# PIC16LF1773 register map
Vendor: Microchip
Registers are 8-bit, read-write, reset 0x0 unless marked. A register's access mark holds for its fields unless they carry their own. Addresses are absolute, and some are shared; only a register's first bit layout is shown; [hi:lo] are bit positions; {n}, {i} and the like mark numbered series.

## txm_mod
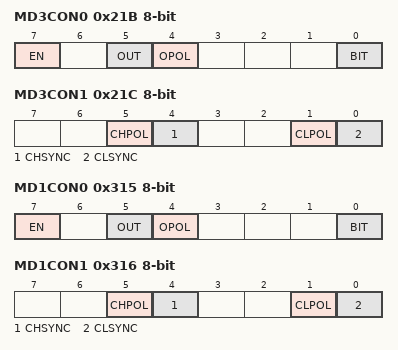
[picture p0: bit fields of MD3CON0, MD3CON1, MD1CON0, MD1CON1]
0x21B MD3CON0
  [7] EN, [5] OUT ro, [4] OPOL, [0] BIT
0x21C MD3CON1
  [5] CHPOL, [4] CHSYNC, [1] CLPOL, [0] CLSYNC
0x21D MD3SRC
  [4:0] MS
0x21E MD3CARL reset not defined — (power-on value ---x0000)
  [4:0] CL
0x21F MD3CARH reset not defined — (power-on value ---x0000)
  [4:0] CH
0x315 MD1CON0
  [7] EN, [5] OUT ro, [4] OPOL, [0] BIT
0x316 MD1CON1
  [5] CHPOL, [4] CHSYNC, [1] CLPOL, [0] CLSYNC
0x317 MD1SRC
  [4:0] MS
0x318 MD1CARL reset not defined — (power-on value ---x0000)
  [4:0] CL
0x319 MD1CARH reset not defined — (power-on value ---x0000)
  [4:0] CH
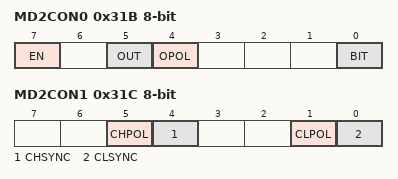
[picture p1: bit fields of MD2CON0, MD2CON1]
0x31B MD2CON0
  [7] EN, [5] OUT ro, [4] OPOL, [0] BIT
0x31C MD2CON1
  [5] CHPOL, [4] CHSYNC, [1] CLPOL, [0] CLSYNC
0x31D MD2SRC
  [4:0] MS
0x31E MD2CARL reset not defined — (power-on value ---x0000)
  [4:0] CL
0x31F MD2CARH reset not defined — (power-on value ---x0000)
  [4:0] CH

## ccp
0x291 CCPR1L reset not defined — (power-on value xxxxxxxx)
  [7:0] RL
0x292 CCPR1H reset not defined — (power-on value xxxxxxxx)
  [7:0] RH
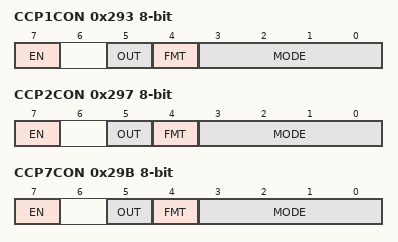
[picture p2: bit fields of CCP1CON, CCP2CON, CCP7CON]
0x293 CCP1CON
  [7] EN, [5] OUT ro, [4] FMT, [3:0] MODE
0x294 CCP1CAP
  [3:0] CTS
0x295 CCPR2L reset not defined — (power-on value xxxxxxxx)
  [7:0] RL
0x296 CCPR2H reset not defined — (power-on value xxxxxxxx)
  [7:0] RH
0x297 CCP2CON
  [7] EN, [5] OUT ro, [4] FMT, [3:0] MODE
0x298 CCP2CAP
  [3:0] CTS
0x299 CCPR7L reset not defined — (power-on value xxxxxxxx)
  [7:0] RL
0x29A CCPR7H reset not defined — (power-on value xxxxxxxx)
  [7:0] RH
0x29B CCP7CON
  [7] EN, [5] OUT ro, [4] FMT, [3:0] MODE
0x29C CCP7CAP
  [3:0] CTS

## tmr
0x413 T4TMR — 8-bit period timer
  [7:0] TMR
0x414 T4PR reset 0xFF
  [7:0] PR
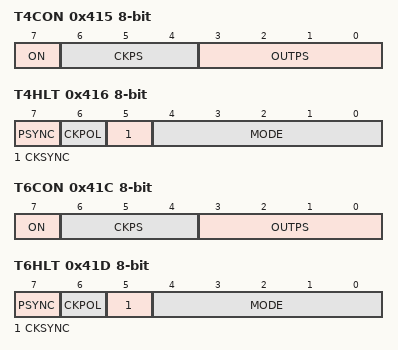
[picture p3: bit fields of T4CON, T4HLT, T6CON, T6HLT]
0x415 T4CON
  [7] ON, [6:4] CKPS, [3:0] OUTPS
0x416 T4HLT
  [7] PSYNC, [6] CKPOL, [5] CKSYNC, [4:0] MODE
0x417 T4CLKCON
  [3:0] CS
0x418 T4RST reset not defined — (power-on value ---x0000)
  [4:0] RSEL
0x41A T6TMR — 8-bit period timer
  [7:0] TMR
0x41B T6PR reset 0xFF
  [7:0] PR
0x41C T6CON
  [7] ON, [6:4] CKPS, [3:0] OUTPS
0x41D T6HLT
  [7] PSYNC, [6] CKPOL, [5] CKSYNC, [4:0] MODE
0x41E T6CLKCON
  [3:0] CS
0x41F T6RST reset not defined — (power-on value ---x0000)
  [4:0] RSEL
0x493 T2TMR — 8-bit period timer
  [7:0] TMR
0x494 T2PR reset 0xFF
  [7:0] PR
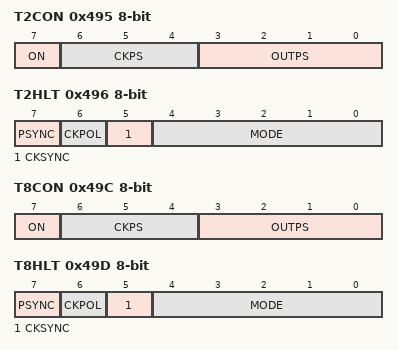
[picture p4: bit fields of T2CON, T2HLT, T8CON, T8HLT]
0x495 T2CON
  [7] ON, [6:4] CKPS, [3:0] OUTPS
0x496 T2HLT
  [7] PSYNC, [6] CKPOL, [5] CKSYNC, [4:0] MODE
0x497 T2CLKCON
  [3:0] CS
0x498 T2RST reset not defined — (power-on value ---x0000)
  [4:0] RSEL
0x49A T8TMR — 8-bit period timer
  [7:0] TMR
0x49B T8PR reset 0xFF
  [7:0] PR
0x49C T8CON
  [7] ON, [6:4] CKPS, [3:0] OUTPS
0x49D T8HLT
  [7] PSYNC, [6] CKPOL, [5] CKSYNC, [4:0] MODE
0x49E T8CLKCON
  [3:0] CS
0x49F T8RST reset not defined — (power-on value ---x0000)
  [4:0] RSEL

## amp_opamp_hvpump
{0x50B+4i} OPA{i}NCHS (i=1..3)
  [3:0] NCH
{0x50C+4i} OPA{i}PCHS (i=1..3)
  [3:0] PCH
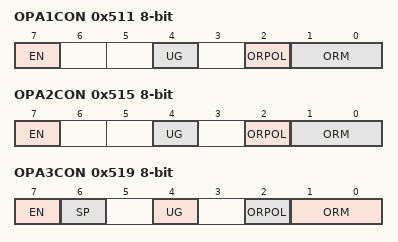
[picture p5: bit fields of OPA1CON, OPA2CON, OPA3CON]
0x511 OPA1CON
  [7] EN, [4] UG, [2] ORPOL, [1:0] ORM
{0x50E+4i} OPA{i}ORS (i=1..3)
  [4:0] ORS
0x515 OPA2CON
  [7] EN, [4] UG, [2] ORPOL, [1:0] ORM
0x519 OPA3CON
  [7] EN, [6] SP, [4] UG, [2] ORPOL, [1:0] ORM

## dac_nbit__ctrl
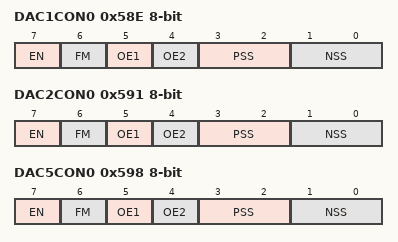
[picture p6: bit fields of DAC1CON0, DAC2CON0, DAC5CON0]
0x58E DAC1CON0
  [7] EN, [6] FM, [5] OE1, [4] OE2, [3:2] PSS, [1:0] NSS
0x58F DAC1REFL
  [7:0] REF
0x590 DAC1REFH
  [7:0] REF
0x591 DAC2CON0
  [7] EN, [6] FM, [5] OE1, [4] OE2, [3:2] PSS, [1:0] NSS
0x592 DAC2REFL
  [7:0] REF
0x593 DAC2REFH
  [7:0] REF
0x598 DAC5CON0
  [7] EN, [6] FM, [5] OE1, [4] OE2, [3:2] PSS, [1:0] NSS
0x599 DAC5REFL
  [7:0] REF
0x59A DAC5REFH
  [7:0] REF

## 5bit_DAC_wNSS
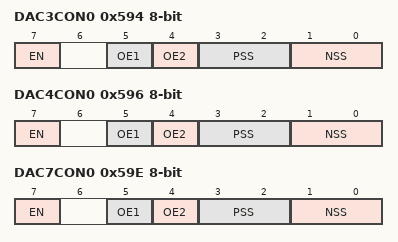
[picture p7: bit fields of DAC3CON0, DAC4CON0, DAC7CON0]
0x594 DAC3CON0
  [7] EN, [5] OE1, [4] OE2, [3:2] PSS, [1:0] NSS
0x595 DAC3REF
  [4:0] DACR
0x596 DAC4CON0
  [7] EN, [5] OE1, [4] OE2, [3:2] PSS, [1:0] NSS
0x597 DAC4REF
  [4:0] DACR
0x59E DAC7CON0
  [7] EN, [5] OE1, [4] OE2, [3:2] PSS, [1:0] NSS
0x59F DAC7REF
  [4:0] DACR
